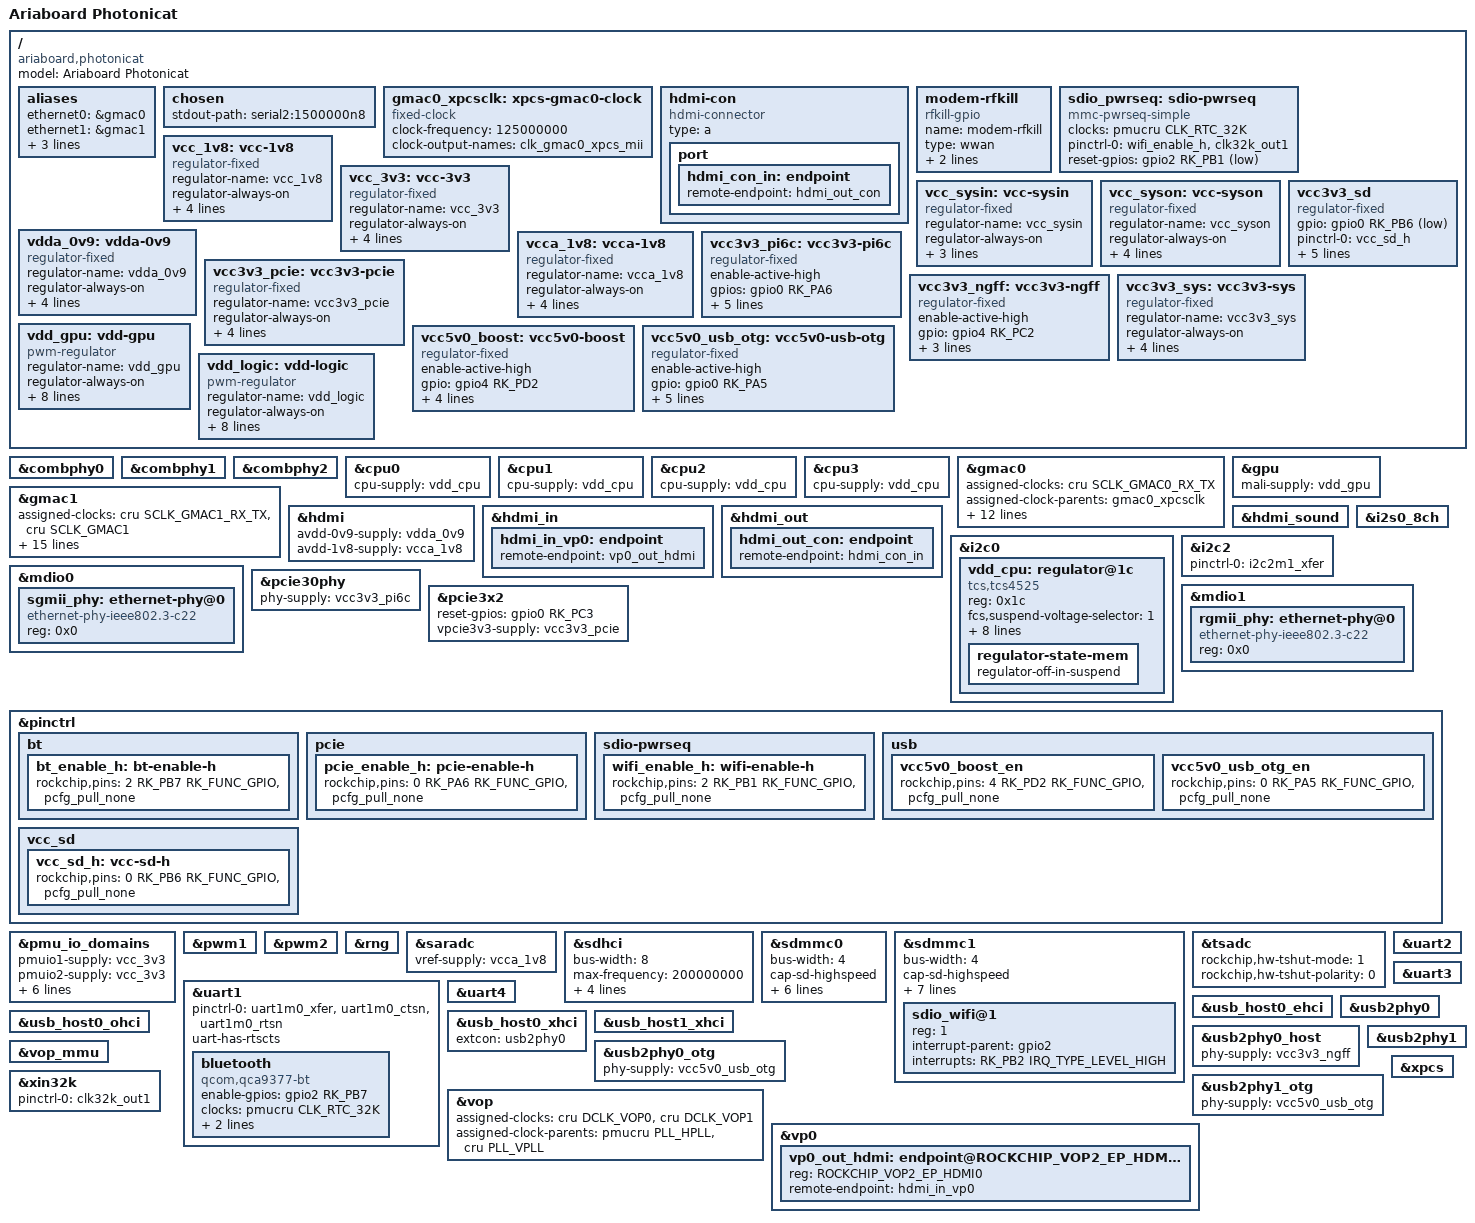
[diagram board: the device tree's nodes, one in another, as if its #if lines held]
// SPDX-License-Identifier: (GPL-2.0+ OR MIT)

/dts-v1/;
#include <dt-bindings/gpio/gpio.h>
#include <dt-bindings/pinctrl/rockchip.h>
#include <dt-bindings/soc/rockchip,vop2.h>
#include "rk3568.dtsi"

/ {
	model = "Ariaboard Photonicat";
	compatible = "ariaboard,photonicat", "rockchip,rk3568";

	aliases {
		ethernet0 = &gmac0;
		ethernet1 = &gmac1;
		mmc0 = &sdhci;
		mmc1 = &sdmmc0;
		mmc2 = &sdmmc1;
	};

	chosen: chosen {
		stdout-path = "serial2:1500000n8";
	};

	gmac0_xpcsclk: xpcs-gmac0-clock {
		compatible = "fixed-clock";
		clock-frequency = <125000000>;
		clock-output-names = "clk_gmac0_xpcs_mii";
		#clock-cells = <0>;
	};

#ifdef DTS_NO_LEGACY
	hdmi-con {
		compatible = "hdmi-connector";
		type = "a";

		port {
			hdmi_con_in: endpoint {
				remote-endpoint = <&hdmi_out_con>;
			};
		};
	};
#endif

	modem-rfkill {
		compatible = "rfkill-gpio";
		name = "modem-rfkill";
		type = "wwan";
		reset-gpios = <&gpio0 RK_PB0 GPIO_ACTIVE_LOW>;
		shutdown-gpios = <&gpio4 RK_PC4 GPIO_ACTIVE_HIGH>;
	};

	sdio_pwrseq: sdio-pwrseq {
		compatible = "mmc-pwrseq-simple";
		clocks = <&pmucru CLK_RTC_32K>;
		clock-names = "ext_clock";
		pinctrl-names = "default";
		pinctrl-0 = <&wifi_enable_h &clk32k_out1>;
		reset-gpios = <&gpio2 RK_PB1 GPIO_ACTIVE_LOW>;
	};

	vcc_1v8: vcc-1v8 {
		compatible = "regulator-fixed";
		regulator-name = "vcc_1v8";
		regulator-always-on;
		regulator-boot-on;
		regulator-min-microvolt = <1800000>;
		regulator-max-microvolt = <1800000>;
		vin-supply = <&vcc3v3_sys>;
	};

	vcc_3v3: vcc-3v3 {
		compatible = "regulator-fixed";
		regulator-name = "vcc_3v3";
		regulator-always-on;
		regulator-boot-on;
		regulator-min-microvolt = <3300000>;
		regulator-max-microvolt = <3300000>;
		vin-supply = <&vcc3v3_sys>;
	};

	vcc_sysin: vcc-sysin {
		compatible = "regulator-fixed";
		regulator-name = "vcc_sysin";
		regulator-always-on;
		regulator-boot-on;
		regulator-min-microvolt = <5000000>;
		regulator-max-microvolt = <5000000>;
	};

	vcc_syson: vcc-syson {
		compatible = "regulator-fixed";
		regulator-name = "vcc_syson";
		regulator-always-on;
		regulator-boot-on;
		regulator-min-microvolt = <5000000>;
		regulator-max-microvolt = <5000000>;
		vin-supply = <&vcc_sysin>;
	};

	vdda_0v9: vdda-0v9 {
		compatible = "regulator-fixed";
		regulator-name = "vdda_0v9";
		regulator-always-on;
		regulator-boot-on;
		regulator-min-microvolt = <900000>;
		regulator-max-microvolt = <900000>;
		vin-supply = <&vcc3v3_sys>;
	};

	vcca_1v8: vcca-1v8 {
		compatible = "regulator-fixed";
		regulator-name = "vcca_1v8";
		regulator-always-on;
		regulator-boot-on;
		regulator-min-microvolt = <1800000>;
		regulator-max-microvolt = <1800000>;
		vin-supply = <&vcc3v3_sys>;
	};

	/* pi6c pcie clock generator */
	vcc3v3_pi6c: vcc3v3-pi6c {
		compatible = "regulator-fixed";
		enable-active-high;
		gpios = <&gpio0 RK_PA6 GPIO_ACTIVE_HIGH>;
		pinctrl-names = "default";
		pinctrl-0 = <&pcie_enable_h>;
		regulator-name = "vcc3v3_pi6c";
		regulator-min-microvolt = <3300000>;
		regulator-max-microvolt = <3300000>;
		vin-supply = <&vcc_syson>;
	};

	/* actually fed by vcc_syson, dependent
	 * on pi6c clock generator
	 */
	vcc3v3_pcie: vcc3v3-pcie {
		compatible = "regulator-fixed";
		regulator-name = "vcc3v3_pcie";
		regulator-always-on;
		regulator-boot-on;
		regulator-min-microvolt = <3300000>;
		regulator-max-microvolt = <3300000>;
		vin-supply = <&vcc3v3_pi6c>;
	};

	vcc3v3_ngff: vcc3v3-ngff {
		compatible = "regulator-fixed";
		enable-active-high;
		gpio = <&gpio4 RK_PC2 GPIO_ACTIVE_HIGH>;
		regulator-name = "vcc3v3_ngff";
		regulator-min-microvolt = <3300000>;
		regulator-max-microvolt = <3300000>;
	};

	vcc3v3_sd: vcc3v3_sd {
		compatible = "regulator-fixed";
		gpio = <&gpio0 RK_PB6 GPIO_ACTIVE_LOW>;
		pinctrl-names = "default";
		pinctrl-0 = <&vcc_sd_h>;
		regulator-boot-on;
		regulator-name = "vcc3v3_sd";
		regulator-min-microvolt = <3300000>;
		regulator-max-microvolt = <3300000>;
		vin-supply = <&vcc_3v3>;
	};

	vcc3v3_sys: vcc3v3-sys {
		compatible = "regulator-fixed";
		regulator-name = "vcc3v3_sys";
		regulator-always-on;
		regulator-boot-on;
		regulator-min-microvolt = <3300000>;
		regulator-max-microvolt = <3300000>;
		vin-supply = <&vcc_syson>;
	};

	vcc5v0_boost: vcc5v0-boost {
		compatible = "regulator-fixed";
		enable-active-high;
		gpio = <&gpio4 RK_PD2 GPIO_ACTIVE_HIGH>;
		pinctrl-names = "default";
		pinctrl-0 = <&vcc5v0_boost_en>;
		regulator-name = "vcc5v0_boost";
		regulator-min-microvolt = <5000000>;
		regulator-max-microvolt = <5000000>;
	};

	vcc5v0_usb_otg: vcc5v0-usb-otg {
		compatible = "regulator-fixed";
		enable-active-high;
		gpio = <&gpio0 RK_PA5 GPIO_ACTIVE_HIGH>;
		pinctrl-names = "default";
		pinctrl-0 = <&vcc5v0_usb_otg_en>;
		regulator-name = "vcc5v0_usb_otg";
		regulator-min-microvolt = <5000000>;
		regulator-max-microvolt = <5000000>;
		vin-supply = <&vcc_sysin>;
	};

	vdd_gpu: vdd-gpu {
		compatible = "pwm-regulator";
		regulator-name = "vdd_gpu";
		regulator-always-on;
		regulator-boot-on;
		regulator-init-microvolt = <900000>;
		regulator-min-microvolt = <800000>;
		regulator-max-microvolt = <1350000>;
		regulator-ramp-delay = <6001>;
		regulator-settling-time-up-us = <250>;

		pwms = <&pwm2 0 5000 1>;
		pwm-supply = <&vcc_syson>;
	};

	vdd_logic: vdd-logic {
		compatible = "pwm-regulator";
		regulator-name = "vdd_logic";
		regulator-always-on;
		regulator-boot-on;
		regulator-init-microvolt = <900000>;
		regulator-min-microvolt = <500000>;
		regulator-max-microvolt = <1350000>;
		regulator-ramp-delay = <6001>;
		regulator-settling-time-up-us = <250>;

		pwms = <&pwm1 0 5000 1>;
		pwm-supply = <&vcc_syson>;
	};
};

&combphy0 {
	status = "okay";
};

&combphy1 {
	status = "okay";
};

&combphy2 {
	status = "okay";
};

&cpu0 {
	cpu-supply = <&vdd_cpu>;
};

&cpu1 {
	cpu-supply = <&vdd_cpu>;
};

&cpu2 {
	cpu-supply = <&vdd_cpu>;
};

&cpu3 {
	cpu-supply = <&vdd_cpu>;
};

&gmac0 {
	assigned-clocks = <&cru SCLK_GMAC0_RX_TX>;
	assigned-clock-parents = <&gmac0_xpcsclk>;
	power-domains = <&power RK3568_PD_PIPE>;
	phys = <&combphy2 PHY_TYPE_SGMII>;
	phy-handle = <&sgmii_phy>;
	phy-mode = "sgmii";
	phy-supply = <&vcc_3v3>;
	pinctrl-names = "default";
	pinctrl-0 = <&gmac0_miim>;
	rockchip,xpcs = <&xpcs>;
	snps,reset-gpio = <&gpio3 RK_PC6 GPIO_ACTIVE_LOW>;
	snps,reset-active-low;
	snps,reset-delays-us = <0 20000 100000>;
	tx_delay = <0xff>;
	rx_delay = <0xff>;
	status = "okay";
};

&gmac1 {
	assigned-clocks = <&cru SCLK_GMAC1_RX_TX>, <&cru SCLK_GMAC1>;
	assigned-clock-parents = <&cru SCLK_GMAC1_RGMII_SPEED>;
	assigned-clock-rates = <0>, <125000000>;
	clock_in_out = "output";
	phy-handle = <&rgmii_phy>;
	phy-mode = "rgmii";
	phy-supply = <&vcc_3v3>;
	pinctrl-names = "default";
	pinctrl-0 = <&gmac1m1_miim
		     &gmac1m1_tx_bus2
		     &gmac1m1_rx_bus2
		     &gmac1m1_rgmii_clk
		     &gmac1m1_rgmii_bus>;
	snps,reset-gpio = <&gpio4 RK_PC0 GPIO_ACTIVE_LOW>;
	snps,reset-active-low;
	snps,reset-delays-us = <0 20000 100000>;
	tx_delay = <0x30>;
	rx_delay = <0x10>;
	status = "okay";
};

#ifdef DTS_NO_LEGACY
&gpu {
	mali-supply = <&vdd_gpu>;
	status = "okay";
};

&hdmi {
	avdd-0v9-supply = <&vdda_0v9>;
	avdd-1v8-supply = <&vcca_1v8>;
	status = "okay";
};

&hdmi_in {
	hdmi_in_vp0: endpoint {
		remote-endpoint = <&vp0_out_hdmi>;
	};
};

&hdmi_out {
	hdmi_out_con: endpoint {
		remote-endpoint = <&hdmi_con_in>;
	};
};

&hdmi_sound {
	status = "okay";
};
#endif

&i2c0 {
	status = "okay";

	vdd_cpu: regulator@1c {
		compatible = "tcs,tcs4525";
		reg = <0x1c>;
		fcs,suspend-voltage-selector = <1>;
		regulator-name = "vdd_cpu";
		regulator-always-on;
		regulator-boot-on;
		regulator-init-microvolt = <900000>;
		regulator-min-microvolt = <712500>;
		regulator-max-microvolt = <1390000>;
		regulator-ramp-delay = <2300>;
		vin-supply = <&vcc_syson>;

		regulator-state-mem {
			regulator-off-in-suspend;
		};
	};
};

&i2c2 {
	pinctrl-names = "default";
	pinctrl-0 = <&i2c2m1_xfer>;
	status = "okay";
};

#ifdef DTS_NO_LEGACY
&i2s0_8ch {
	status = "okay";
};
#endif

&mdio0 {
	sgmii_phy: ethernet-phy@0 {
		compatible = "ethernet-phy-ieee802.3-c22";
		reg = <0x0>;
	};
};

&mdio1 {
	rgmii_phy: ethernet-phy@0 {
		compatible = "ethernet-phy-ieee802.3-c22";
		reg = <0x0>;
	};
};

&pcie30phy {
	phy-supply = <&vcc3v3_pi6c>;
	status = "okay";
};

&pcie3x2 {
	reset-gpios = <&gpio0 RK_PC3 GPIO_ACTIVE_HIGH>;
	vpcie3v3-supply = <&vcc3v3_pcie>;
	status = "okay";
};

&pinctrl {
	bt {
		bt_enable_h: bt-enable-h {
			rockchip,pins = <2 RK_PB7 RK_FUNC_GPIO &pcfg_pull_none>;
		};
	};

	pcie {
		pcie_enable_h: pcie-enable-h {
			rockchip,pins = <0 RK_PA6 RK_FUNC_GPIO &pcfg_pull_none>;
		};
	};

	sdio-pwrseq {
		wifi_enable_h: wifi-enable-h {
			rockchip,pins = <2 RK_PB1 RK_FUNC_GPIO &pcfg_pull_none>;
		};
	};

	usb {
		vcc5v0_boost_en: vcc5v0_boost_en {
			rockchip,pins = <4 RK_PD2 RK_FUNC_GPIO &pcfg_pull_none>;
		};

		vcc5v0_usb_otg_en: vcc5v0_usb_otg_en {
			rockchip,pins = <0 RK_PA5 RK_FUNC_GPIO &pcfg_pull_none>;
		};
	};

	vcc_sd {
		vcc_sd_h: vcc-sd-h {
			rockchip,pins = <0 RK_PB6 RK_FUNC_GPIO &pcfg_pull_none>;
		};
	};
};

&pmu_io_domains {
	pmuio1-supply = <&vcc_3v3>;
	pmuio2-supply = <&vcc_3v3>;
	vccio1-supply = <&vcc_3v3>;
	vccio3-supply = <&vcc_3v3>;
	vccio4-supply = <&vcc_1v8>;
	vccio5-supply = <&vcc_3v3>;
	vccio6-supply = <&vcc_3v3>;
	vccio7-supply = <&vcc_3v3>;
	status = "okay";
};

&pwm1 {
	status = "okay";
};

&pwm2 {
	status = "okay";
};

&rng {
	status = "okay";
};

&saradc {
	vref-supply = <&vcca_1v8>;
	status = "okay";
};

&sdhci {
	bus-width = <8>;
	max-frequency = <200000000>;
	non-removable;
	pinctrl-names = "default";
	pinctrl-0 = <&emmc_bus8 &emmc_clk &emmc_cmd>;
	vmmc-supply = <&vcc_3v3>;
	vqmmc-supply = <&vcc_1v8>;
};

&sdmmc0 {
	bus-width = <4>;
	cap-sd-highspeed;
	cd-gpios = <&gpio0 RK_PB5 GPIO_ACTIVE_LOW>;
	disable-wp;
	no-1-8-v;
	pinctrl-names = "default";
	pinctrl-0 = <&sdmmc0_bus4 &sdmmc0_clk &sdmmc0_cmd>;
	vmmc-supply = <&vcc3v3_sd>;
	vqmmc-supply = <&vcc_3v3>;
	status = "okay";
};

&sdmmc1 {
	bus-width = <4>;
	cap-sd-highspeed;
	keep-power-in-suspend;
	mmc-pwrseq = <&sdio_pwrseq>;
	non-removable;
	pinctrl-names = "default";
	pinctrl-0 = <&sdmmc1_bus4 &sdmmc1_clk &sdmmc1_cmd>;
	sd-uhs-sdr104;
	vmmc-supply = <&vcc3v3_sys>;
	vqmmc-supply = <&vcc_1v8>;
	status = "okay";

	sdio_wifi@1 {
		reg = <1>;
		interrupt-parent = <&gpio2>;
		interrupts = <RK_PB2 IRQ_TYPE_LEVEL_HIGH>;
		interrupt-names = "host-wake";
	};
};

&tsadc {
	rockchip,hw-tshut-mode = <1>;
	rockchip,hw-tshut-polarity = <0>;
	status = "okay";
};

&uart1 {
	pinctrl-names = "default";
	pinctrl-0 = <&uart1m0_xfer &uart1m0_ctsn &uart1m0_rtsn>;
	status = "okay";
	uart-has-rtscts;

	bluetooth {
		compatible = "qcom,qca9377-bt";
		enable-gpios = <&gpio2 RK_PB7 GPIO_ACTIVE_HIGH>;
		clocks = <&pmucru CLK_RTC_32K>;
		clock-names = "lpo";
		pinctrl-names = "default";
		pinctrl-0 = <&bt_enable_h>;
		vddio-supply = <&vcc_1v8>;
	};
};

&uart2 {
	status = "okay";
};

&uart3 {
	status = "okay";
};

&uart4 {
	status = "okay";
};

&usb_host0_ehci {
	status = "okay";
};

&usb_host0_ohci {
	status = "okay";
};

&usb_host0_xhci {
	extcon = <&usb2phy0>;
	status = "okay";
};

&usb_host1_xhci {
	status = "okay";
};

&usb2phy0 {
	status = "okay";
};

&usb2phy0_host {
	phy-supply = <&vcc3v3_ngff>;
	status = "okay";
};

&usb2phy0_otg {
	phy-supply = <&vcc5v0_usb_otg>;
	status = "okay";
};

&usb2phy1 {
	status = "okay";
};

&usb2phy1_otg {
	phy-supply = <&vcc5v0_usb_otg>;
	status = "okay";
};

#ifdef DTS_NO_LEGACY
&vop {
	assigned-clocks = <&cru DCLK_VOP0>, <&cru DCLK_VOP1>;
	assigned-clock-parents = <&pmucru PLL_HPLL>, <&cru PLL_VPLL>;
	status = "okay";
};

&vop_mmu {
	status = "okay";
};

&vp0 {
	vp0_out_hdmi: endpoint@ROCKCHIP_VOP2_EP_HDMI0 {
		reg = <ROCKCHIP_VOP2_EP_HDMI0>;
		remote-endpoint = <&hdmi_in_vp0>;
	};
};
#endif

&xin32k {
	pinctrl-names = "default";
	pinctrl-0 = <&clk32k_out1>;
};

&xpcs {
	status = "okay";
};
